# R40 register map
Vendor: Allwinner; Series: R40; File version: 0.1
CPU: CA7 0, little endian, MPU, FPU, double-precision FPU, 0 interrupt priority bits
Registers are 32-bit, read-write, reset 0x0 unless marked. A register's access mark holds for its fields unless they carry their own. Offsets are from the block's base; [hi:lo] are bit positions; {n}, {i} and the like mark numbered series; 'fields as' and 'values as' point back to an identical list.

## CPU_Configuration
Base 0x01C25C00
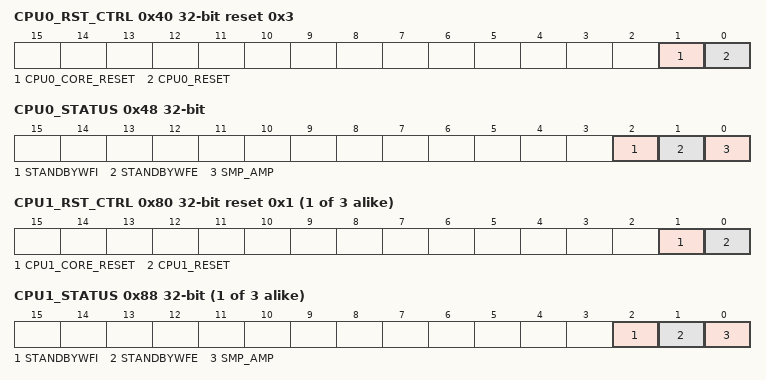
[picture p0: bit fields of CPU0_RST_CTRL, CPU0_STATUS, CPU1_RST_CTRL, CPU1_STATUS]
0x40 CPU0_RST_CTRL reset 0x3 — CPU0 Reset Control
  [1] CPU0_CORE_RESET — These are the primary reset signals which initialize the processor logic in the processor power domains, not including the debug, breakpoint and watchpoint logic. 0: Assert 1: De-assert
    0=Assert; 1=deassert
  [0] CPU0_RESET — CPU0 Reset Assert. These power-on reset signals initialize all the processor logic, including CPU Debug, and breakpoint and watch point logic in the processor power domains. They do not reset debug logic in the debug power domain. 0: Assert 1: De-assert
    0=Assert; 1=deassert
0x44 CPU0_CTRL_REG — CPU0 Control Register
  [0] CPU0_CP15_WRITE_DISABLE — Disable write access to certain CP15 registers. 0: Enable 1: Disable
    0=Enable; 1=Disable
0x48 CPU0_STATUS
  [2] STANDBYWFI ro — Indicates if the processor is in WFI standby mode 0: Processor is not in WFI standby mode 1: Processor is in WFI standby mode
    0=not_in (Processor is not in WFI standby mode); 1=in (Processor is in WFI standby mode)
  [1] STANDBYWFE ro — Indicates if the processor is in the WFE standby mode 0: Processor is not in WFE standby mode 1: Processor is in WFE standby mode
    0=not_in (Processor is not in WFE standby mode); 1=in (Processor is in WFE standby mode)
  [0] SMP_AMP ro — 0: AMP mode 1: SMP mode
    0=AMP_mode; 1=SMP_mode
{0x40+0x40*i} CPU{i}_RST_CTRL reset 0x1 (i=1..3) — CPU{i} Reset Control
  [1] CPU{i}_CORE_RESET — These are the primary reset signals which initialize the processor logic in the processor power domains, not including the debug, breakpoint and watchpoint logic. 0: Assert 1: De-assert
    0=Assert; 1=deassert
  [0] CPU{i}_RESET — CPU{i} Reset Assert. These power-on reset signals initialize all the processor logic, including CPU Debug, and breakpoint and watch point logic in the processor power domains. They do not reset debug logic in the debug power domain. 0: Assert 1: De-assert
    0=Assert; 1=deassert
0x84 CPU1_CTRL_REG — CPU1 Control Register
  [0] CPU1_CP15_WRITE_DISABLE — Disable write access to certain CP15 registers. 0: Enable 1: Disable
    0=Enable; 1=Disable
{0x48+0x40*i} CPU{i}_STATUS (i=1..3)
  [2] STANDBYWFI ro — Indicates if the processor is in WFI standby mode 0: Processor is not in WFI standby mode. 1: Processor is in WFI standby mode
    0=not_in (Processor is not in WFI standby mode.); 1=in (Processor is in WFI standby mode)
  [1] STANDBYWFE ro — Indicates if the processor is in the WFE standby mode 0: Processor is not in WFE standby mode 1: Processor is in WFE standby mode
    values as CPU0_STATUS.STANDBYWFE
  [0] SMP_AMP ro — 0: AMP mode 1: SMP mode
    0=AMP_mode; 1=SMP_mode
0xC4 CPU2_CTRL_REG — CPU2 Control Register
  [0] CPU_CP15_WRITE_DISABLE — Disable write access to certain CP15 registers. 0: Enable 1: Disable
    0=Enable; 1=Disable
0x104 CPU3_CTRL_REG — CPU3 Control Register
  fields as CPU2_CTRL_REG
0x110 CPUX_PWROFF_GATING_REG — CPUX Power Off Gating(Power clamp) Register
  [3:0] PWROFF_GATING_3_0 — PWROFF_GATING[3:0] Gating the corresponding modules when the corresponding CPU power off. 0: Invalid 1: Valid The corresponding bit should be set to 1 before the corresponding CPU power-off while it should be set to 0 after CPU power-on.
0x120 CPU0_PWR_SWITCH_REG — CPU0 Power Switch Control Register
  [7:0] CPU_PWR_SWITCH_7_0 — CPU_PWR_SWITCH[7:0] 0x00: Power On 0xFF: Power Off
    0=Power_On; 255=Power_Off
0x124 CPU1_PWR_SWITCH_REG — CPU1 Power Switch Control Register
  fields as CPU0_PWR_SWITCH_REG
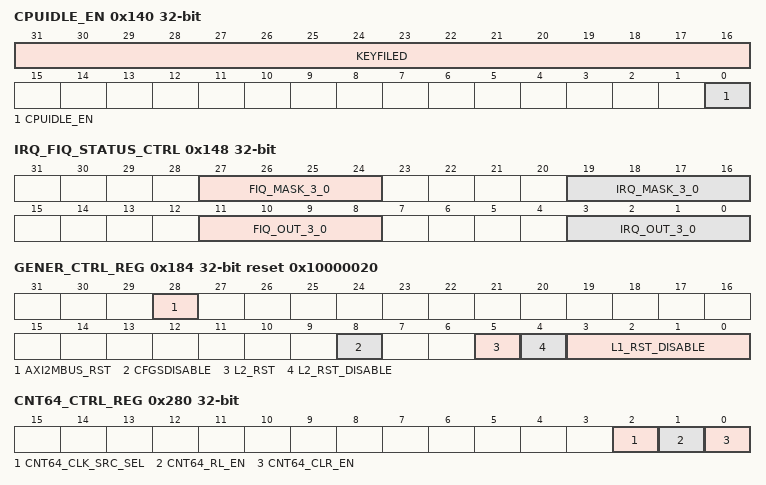
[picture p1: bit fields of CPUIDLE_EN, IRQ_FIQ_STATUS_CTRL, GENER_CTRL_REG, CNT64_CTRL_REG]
0x140 CPUIDLE_EN — CPUIDLE Enable Control Register
  [31:16] KEYFILED — Only the register can be written with 0x16AAXXXX at first(X means any value),then write 0xAA16000x,the `x`(x stand for 0 or 1) can be written into the bit0.
  [0] CPUIDLE_EN — 0: Disable 1: Enable
    0=Disable; 1=Enable
0x144 CLOSE_FLAG — Close Core Flag Register
  [3:0] CLOSE_CORE_3_0 — CLOSE_CORE[3:0] 0: Normal 1: Start to close core Only the corresponding core could set the corresponding bit filed.The bit will be cleared after the corresponding core power-off.
0x148 IRQ_FIQ_STATUS_CTRL — IRQ_FIQ Output Status and Control Register
  [27:24] FIQ_MASK_3_0 — FIQ_MASK[3:0] FIQ output mask to this module 0: Normal 1: Mask
  [19:16] IRQ_MASK_3_0 — IRQ_MASK[3:0] IRQ output mask to this module 0: Normal 1: Mask
  [11:8] FIQ_OUT_3_0 ro — FIQ_OUT[3:0] FIQ wakeup output 0: Normal 1: FIQ Happen
  [3:0] IRQ_OUT_3_0 ro — IRQ_OUT[3:0] IRQ wakeup output 0: Normal 1: IRQ Happen
0x150 PWR_SW_DELAY reset 0xA — Power Switch Operation Delay Register
  [7:0] DELAY_TMR — Delay time(1~255us) when setting power switch value.
0x154 CONFIG_DELAY reset 0x1 — Configuration Delay Register
  [7:0] DELAY_TMR — Delay time(1~255us) between different steps.
0x158 PWR_DOWN_CFG reset 0xFF — Power Down Configuration Register
  [7:0] SET — Set this value to power switch register when CPUx power down.
0x160 PWR_UP_CFG0 reset 0xFE — Power Up Configuration Register0
  [7:0] SET — Set this value to power switch register when CPUx power up.
0x164 PWR_UP_CFG1 reset 0xFC — Power Up Configuration Register1
  fields as PWR_UP_CFG0
0x168 PWR_UP_CFG2 reset 0xF8 — Power Up Configuration Register2
  fields as PWR_UP_CFG0
0x16C PWR_UP_CFG3 reset 0xF0 — Power Up Configuration Register3
  fields as PWR_UP_CFG0
0x170 PWR_UP_CFG4 reset 0xC0 — Power Up Configuration Register4
  fields as PWR_UP_CFG0
0x174 PWR_UP_CFG5 — Power Up Configuration Register5
  fields as PWR_UP_CFG0
0x184 GENER_CTRL_REG reset 0x10000020 — General Control Register
  [28] AXI2MBUS_RST — AXI2MBUS logic circuit reset 0: Assert 1: De-assert
    0=Assert; 1=deassert
  [8] CFGSDISABLE — Disable write access to some secure GIC registers.
  [5] L2_RST — L2 Reset.(SCU global reset) 0: Apply reset to shared L2 memory system controller. 1: Do not apply reset to shared L2 memory system controller.
    0=Apply reset to shared L2 memory system controller; 1=Do not apply reset to shared L2 memory system controller
  [4] L2_RST_DISABLE — Disable automatic L2 cache invalidate at reset 0: L2 cache is reset by hardware. 1: L2 cache is not reset by hardware.
    0=reset (L2 cache is reset by hardware.); 1=not_reset (L2 cache is not reset by hardware.)
  [3:0] L1_RST_DISABLE — L1 Reset Disable[3:0]. 0: L1 cache is reset by hardware. 1: L1 cache is not reset by hardware.
0x190 EVENT_IN_REG — Event Input Register
  [0] EVENT_IN — Event input that can wake-up CPUx from WFE standby mode.
0x280 CNT64_CTRL_REG — 64-bit Counter Control Register
  [2] CNT64_CLK_SRC_SEL — 64-bit Counter Clock Source Select. 0: OSC24M 1: /
    0=OSC24M
  [1] CNT64_RL_EN — 64-bit Counter Read Latch Enable. 0: No effect 1: Latch the 64-bit counter to the Low/High registers and it will change to zero after the registers are latched.
    0=No_effect; 1=Latch the 64-bit counter to the Low/High registers and it will change to zero after the registers are latched
  [0] CNT64_CLR_EN — 64-bit Counter Clear Enable. 0: No effect 1: Clear the 64-bit Counter Low/High registers and it will change to zero after the registers are cleared. It is not recommended to clear this counter arbitrarily.
    0=No_effect; 1=Clear the 64-bit Counter Low/High registers and it will change to zero after the registers are cleared. It is not recommended to clear this counter arbitrarily.
0x284 CNT64_LOW_REG — 64-bit Counter Low Register
  [31:0] CNT64_LO — 64-bit Counter [31:0].
0x288 CNT64_HIGH_REG — 64-bit Counter High Register
  [31:0] CNT64_HI — 64-bit Counter [63:32].
